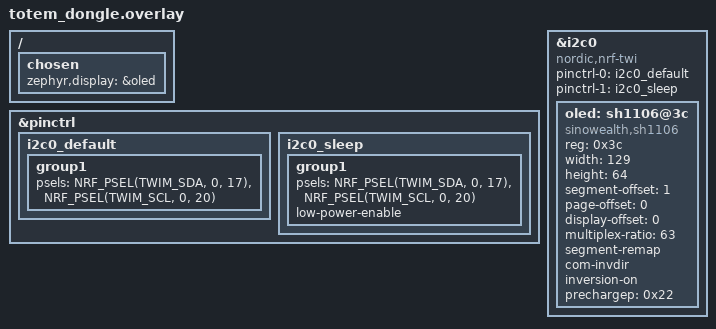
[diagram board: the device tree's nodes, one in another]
/*
 * SH1106 OLED on the Eyelash Sofle dongle (nice!nano v2 compatible).
 * Wiring matches eyelash_sofle_central_dongle.overlay: SDA P0.17, SCL P0.20, addr 0x3c.
 * The mock kscan and physical layout come from the upstream totem_dongle shield.
 */

&pinctrl {
    i2c0_default: i2c0_default {
        group1 {
            psels = <NRF_PSEL(TWIM_SDA, 0, 17)>, <NRF_PSEL(TWIM_SCL, 0, 20)>;
        };
    };
    i2c0_sleep: i2c0_sleep {
        group1 {
            psels = <NRF_PSEL(TWIM_SDA, 0, 17)>, <NRF_PSEL(TWIM_SCL, 0, 20)>;
            low-power-enable;
        };
    };
};

&i2c0 {
    status = "okay";
    compatible = "nordic,nrf-twi";
    pinctrl-0 = <&i2c0_default>;
    pinctrl-1 = <&i2c0_sleep>;
    pinctrl-names = "default", "sleep";

    oled: sh1106@3c {
        compatible = "sinowealth,sh1106";
        reg = <0x3c>;
        width = <129>;
        height = <64>;
        segment-offset = <1>;
        page-offset = <0>;
        display-offset = <0>;
        multiplex-ratio = <63>;
        segment-remap;
        com-invdir;
        inversion-on;
        prechargep = <0x22>;
    };
};

/ {
    chosen {
        zephyr,display = &oled;
    };
};
